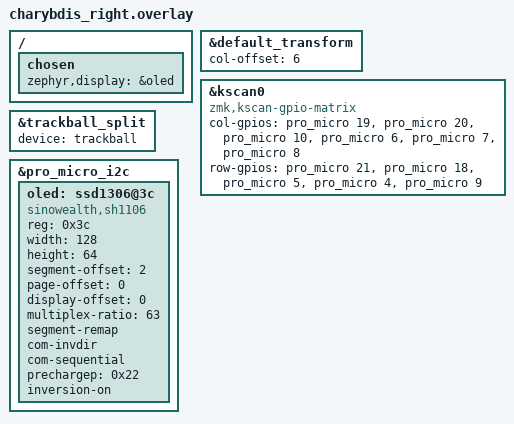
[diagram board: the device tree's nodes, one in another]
#include "charybdis.dtsi"
#include "charybdis_3610.dtsi"
#include "split_input_common.dtsi"

&default_transform {
	col-offset = <6>;
};

&kscan0 {
	compatible = "zmk,kscan-gpio-matrix";
	
	col-gpios
		= <&pro_micro 19 (GPIO_ACTIVE_HIGH | GPIO_PULL_DOWN)>
		, <&pro_micro 20 (GPIO_ACTIVE_HIGH | GPIO_PULL_DOWN)>
		, <&pro_micro 10 (GPIO_ACTIVE_HIGH | GPIO_PULL_DOWN)>
		, <&pro_micro 6 (GPIO_ACTIVE_HIGH | GPIO_PULL_DOWN)>
		, <&pro_micro 7 (GPIO_ACTIVE_HIGH | GPIO_PULL_DOWN)>
		, <&pro_micro 8 (GPIO_ACTIVE_HIGH | GPIO_PULL_DOWN)>
		;

	row-gpios
		= <&pro_micro 21 GPIO_ACTIVE_HIGH>
		, <&pro_micro 18 GPIO_ACTIVE_HIGH>
		, <&pro_micro 5 GPIO_ACTIVE_HIGH>
		, <&pro_micro 4 GPIO_ACTIVE_HIGH>
		, <&pro_micro 9 GPIO_ACTIVE_HIGH>
		;
};

&trackball_split {
    device = <&trackball>;
};

/ {
    chosen {
        zephyr,display = &oled;
    };
};

&pro_micro_i2c {
    status = "okay";

    oled: ssd1306@3c {
        compatible = "sinowealth,sh1106";
        reg = <0x3c>;
        width = <128>;
        height = <64>;
        segment-offset = <2>;   /* Смещение пикселей для 1.3" OLED */
        page-offset = <0>;
        display-offset = <0>;
        multiplex-ratio = <63>;
        segment-remap;
        com-invdir;
        com-sequential;
        prechargep = <0x22>;
        inversion-on;
    };
};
